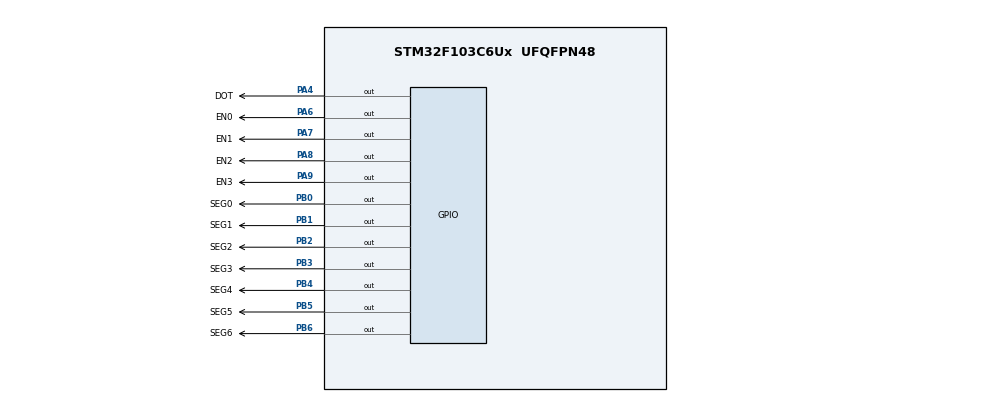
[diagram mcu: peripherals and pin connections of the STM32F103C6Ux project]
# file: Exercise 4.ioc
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Mcu.Family=STM32F1
Mcu.Name=STM32F103C6Ux
Mcu.Package=UFQFPN48
NVIC.PriorityGroup=NVIC_PRIORITYGROUP_4
NVIC.TIM1_BRK_IRQn=true\:0\:0\:false\:false\:true\:true\:true
NVIC.TIM1_CC_IRQn=true\:0\:0\:false\:false\:true\:true\:true
NVIC.TIM1_TRG_COM_IRQn=true\:0\:0\:false\:false\:true\:true\:true
NVIC.TIM1_UP_IRQn=true\:0\:0\:false\:false\:true\:true\:true
NVIC.TIM2_IRQn=true\:0\:0\:false\:false\:true\:true\:true
PA4.GPIO_Label=DOT
PA4.Signal=GPIO_Output
PA6.GPIO_Label=EN0
PA6.Signal=GPIO_Output
PA7.GPIO_Label=EN1
PA7.Signal=GPIO_Output
PA8.GPIO_Label=EN2
PA8.Signal=GPIO_Output
PA9.GPIO_Label=EN3
PA9.Signal=GPIO_Output
PB0.GPIO_Label=SEG0
PB0.Signal=GPIO_Output
PB1.GPIO_Label=SEG1
PB1.Signal=GPIO_Output
PB2.GPIO_Label=SEG2
PB2.Signal=GPIO_Output
PB3.GPIO_Label=SEG3
PB3.Signal=GPIO_Output
PB4.GPIO_Label=SEG4
PB4.Signal=GPIO_Output
PB5.GPIO_Label=SEG5
PB5.Signal=GPIO_Output
PB6.GPIO_Label=SEG6
PB6.Signal=GPIO_Output
ProjectManager.HeapSize=0x200
ProjectManager.StackSize=0x400
ProjectManager.TargetToolchain=STM32CubeIDE
RCC.APB1Freq_Value=8000000
RCC.APB2Freq_Value=8000000
TIM1.Period=9
TIM1.Prescaler=7999
TIM2.Period=9
TIM2.Prescaler=7999
VP_SYS_VS_ND.Mode=No_Debug
VP_TIM1_VS_ClockSourceINT.Mode=Internal
VP_TIM2_VS_ClockSourceINT.Mode=Internal
board=custom

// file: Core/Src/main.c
/* USER CODE BEGIN Header */
/**
  ******************************************************************************
  * @file           : main.c
  * @brief          : Main program body
  ******************************************************************************
  * @attention
  *
  * <h2><center>&copy; Copyright (c) 2023 STMicroelectronics.
  * All rights reserved.</center></h2>
  *
  * This software component is licensed by ST under BSD 3-Clause license,
  * the "License"; You may not use this file except in compliance with the
  * License. You may obtain a copy of the License at:
  *                        opensource.org/licenses/BSD-3-Clause
  *
  ******************************************************************************
  */
/* USER CODE END Header */
#include "main.h"

/* USER CODE BEGIN Includes */
#include "software_timer.h"
/* USER CODE END Includes */

TIM_HandleTypeDef htim1;
TIM_HandleTypeDef htim2;

void SystemClock_Config(void);
static void MX_GPIO_Init(void);
static void MX_TIM1_Init(void);
static void MX_TIM2_Init(void);

int main(void)
{

  /* MCU Configuration--------------------------------------------------------*/

  /* Reset of all peripherals, Initializes the Flash interface and the Systick. */
  HAL_Init();

  /* Configure the system clock */
  SystemClock_Config();

  /* Initialize all configured peripherals */
  MX_GPIO_Init();
  MX_TIM1_Init();
  MX_TIM2_Init();
  /* USER CODE BEGIN 2 */
  HAL_TIM_Base_Start_IT(&htim1);
  HAL_TIM_Base_Start_IT(&htim2);
  /* USER CODE END 2 */

  /* Infinite loop */
  void display7SEG(int num) {
     	  char segNumber[10] = {0xC0, 0xF9, 0xA4, 0xB0, 0x99, 0x92, 0x82, 0xF8, 0x80, 0x90};
         for (int i = 0; i < 7; ++i) {
         	  HAL_GPIO_WritePin(GPIOB, GPIO_PIN_0 << i, (segNumber[num] >> i) & 1);
           }
       }
   int index_led = 0;
   int led_buffer [4] = {1,2,3,0};
   void update7SEG(int index){
 	  switch (index){
 	  	  case 0:
 	  		  display7SEG(led_buffer[0]);
 	  		  HAL_GPIO_WritePin(GPIOA, EN0_Pin, RESET);
 	  		  HAL_GPIO_WritePin(GPIOA, EN1_Pin, SET);
 	  		  HAL_GPIO_WritePin(GPIOA, EN2_Pin, SET);
 	  		  HAL_GPIO_WritePin(GPIOA, EN3_Pin, SET);
 	  		  break;
 	  	  case 1:
 	  		  display7SEG(led_buffer[1]);
 	  		  HAL_GPIO_WritePin(GPIOA, EN0_Pin, SET);
 	  		  HAL_GPIO_WritePin(GPIOA, EN1_Pin, RESET);
 	  		  HAL_GPIO_WritePin(GPIOA, EN2_Pin, SET);
 	  		  HAL_GPIO_WritePin(GPIOA, EN3_Pin, SET);
 	  		  break;
 	  	  case 2:
 	  		  display7SEG(led_buffer[2]);
 	  		  HAL_GPIO_WritePin(GPIOA, EN0_Pin, SET);
 	  		  HAL_GPIO_WritePin(GPIOA, EN1_Pin, SET);
 	  	      HAL_GPIO_WritePin(GPIOA, EN2_Pin, RESET);
 	  		  HAL_GPIO_WritePin(GPIOA, EN3_Pin, SET);
 	  		  break;
 	  	  case 3:
 	  		  display7SEG(led_buffer[3]);
 	  		  HAL_GPIO_WritePin(GPIOA, EN0_Pin, SET);
 	  		  HAL_GPIO_WritePin(GPIOA, EN1_Pin, SET);
 	  		  HAL_GPIO_WritePin(GPIOA, EN2_Pin, SET);
 	  		  HAL_GPIO_WritePin(GPIOA, EN3_Pin, RESET);
 	  		  break;
 	  	  default:
 	  		  break;
 	  }
   }
   setTimer1(01);
   setTimer2(01);
  /* USER CODE BEGIN WHILE */
  while (1)
  {
	  if (timer1_flag == 1){
	  	  setTimer1(100);
	  	  HAL_GPIO_TogglePin(GPIOA, DOT_Pin);
	  }
	  if (timer2_flag == 1){
		  setTimer2(25);
		  update7SEG(index_led++);
		  if(index_led >= 4) index_led = 0;
	  }
    /* USER CODE END WHILE */

  }
}

void SystemClock_Config(void)
{
  RCC_OscInitTypeDef RCC_OscInitStruct = {0};
  RCC_ClkInitTypeDef RCC_ClkInitStruct = {0};

  /** Initializes the RCC Oscillators according to the specified parameters
  * in the RCC_OscInitTypeDef structure.
  */
  RCC_OscInitStruct.OscillatorType = RCC_OSCILLATORTYPE_HSI;
  RCC_OscInitStruct.HSIState = RCC_HSI_ON;
  RCC_OscInitStruct.HSICalibrationValue = RCC_HSICALIBRATION_DEFAULT;
  RCC_OscInitStruct.PLL.PLLState = RCC_PLL_NONE;
  if (HAL_RCC_OscConfig(&RCC_OscInitStruct) != HAL_OK)
  {
    Error_Handler();
  }
  /** Initializes the CPU, AHB and APB buses clocks
  */
  RCC_ClkInitStruct.ClockType = RCC_CLOCKTYPE_HCLK|RCC_CLOCKTYPE_SYSCLK
                              |RCC_CLOCKTYPE_PCLK1|RCC_CLOCKTYPE_PCLK2;
  RCC_ClkInitStruct.SYSCLKSource = RCC_SYSCLKSOURCE_HSI;
  RCC_ClkInitStruct.AHBCLKDivider = RCC_SYSCLK_DIV1;
  RCC_ClkInitStruct.APB1CLKDivider = RCC_HCLK_DIV1;
  RCC_ClkInitStruct.APB2CLKDivider = RCC_HCLK_DIV1;

  if (HAL_RCC_ClockConfig(&RCC_ClkInitStruct, FLASH_LATENCY_0) != HAL_OK)
  {
    Error_Handler();
  }
}

static void MX_TIM1_Init(void)
{

  TIM_ClockConfigTypeDef sClockSourceConfig = {0};
  TIM_MasterConfigTypeDef sMasterConfig = {0};

  htim1.Instance = TIM1;
  htim1.Init.Prescaler = 7999;
  htim1.Init.CounterMode = TIM_COUNTERMODE_UP;
  htim1.Init.Period = 9;
  htim1.Init.ClockDivision = TIM_CLOCKDIVISION_DIV1;
  htim1.Init.RepetitionCounter = 0;
  htim1.Init.AutoReloadPreload = TIM_AUTORELOAD_PRELOAD_DISABLE;
  if (HAL_TIM_Base_Init(&htim1) != HAL_OK)
  {
    Error_Handler();
  }
  sClockSourceConfig.ClockSource = TIM_CLOCKSOURCE_INTERNAL;
  if (HAL_TIM_ConfigClockSource(&htim1, &sClockSourceConfig) != HAL_OK)
  {
    Error_Handler();
  }
  sMasterConfig.MasterOutputTrigger = TIM_TRGO_RESET;
  sMasterConfig.MasterSlaveMode = TIM_MASTERSLAVEMODE_DISABLE;
  if (HAL_TIMEx_MasterConfigSynchronization(&htim1, &sMasterConfig) != HAL_OK)
  {
    Error_Handler();
  }

}

static void MX_TIM2_Init(void)
{

  TIM_ClockConfigTypeDef sClockSourceConfig = {0};
  TIM_MasterConfigTypeDef sMasterConfig = {0};

  htim2.Instance = TIM2;
  htim2.Init.Prescaler = 7999;
  htim2.Init.CounterMode = TIM_COUNTERMODE_UP;
  htim2.Init.Period = 9;
  htim2.Init.ClockDivision = TIM_CLOCKDIVISION_DIV1;
  htim2.Init.AutoReloadPreload = TIM_AUTORELOAD_PRELOAD_DISABLE;
  if (HAL_TIM_Base_Init(&htim2) != HAL_OK)
  {
    Error_Handler();
  }
  sClockSourceConfig.ClockSource = TIM_CLOCKSOURCE_INTERNAL;
  if (HAL_TIM_ConfigClockSource(&htim2, &sClockSourceConfig) != HAL_OK)
  {
    Error_Handler();
  }
  sMasterConfig.MasterOutputTrigger = TIM_TRGO_RESET;
  sMasterConfig.MasterSlaveMode = TIM_MASTERSLAVEMODE_DISABLE;
  if (HAL_TIMEx_MasterConfigSynchronization(&htim2, &sMasterConfig) != HAL_OK)
  {
    Error_Handler();
  }

}

static void MX_GPIO_Init(void)
{
  GPIO_InitTypeDef GPIO_InitStruct = {0};

  /* GPIO Ports Clock Enable */
  __HAL_RCC_GPIOA_CLK_ENABLE();
  __HAL_RCC_GPIOB_CLK_ENABLE();

  /*Configure GPIO pin Output Level */
  HAL_GPIO_WritePin(GPIOA, DOT_Pin|EN0_Pin|EN1_Pin|EN2_Pin
                          |EN3_Pin, GPIO_PIN_RESET);

  /*Configure GPIO pin Output Level */
  HAL_GPIO_WritePin(GPIOB, SEG0_Pin|SEG1_Pin|SEG2_Pin|SEG3_Pin
                          |SEG4_Pin|SEG5_Pin|SEG6_Pin, GPIO_PIN_RESET);

  /*Configure GPIO pins : DOT_Pin EN0_Pin EN1_Pin EN2_Pin
                           EN3_Pin */
  GPIO_InitStruct.Pin = DOT_Pin|EN0_Pin|EN1_Pin|EN2_Pin
                          |EN3_Pin;
  GPIO_InitStruct.Mode = GPIO_MODE_OUTPUT_PP;
  GPIO_InitStruct.Pull = GPIO_NOPULL;
  GPIO_InitStruct.Speed = GPIO_SPEED_FREQ_LOW;
  HAL_GPIO_Init(GPIOA, &GPIO_InitStruct);

  /*Configure GPIO pins : SEG0_Pin SEG1_Pin SEG2_Pin SEG3_Pin
                           SEG4_Pin SEG5_Pin SEG6_Pin */
  GPIO_InitStruct.Pin = SEG0_Pin|SEG1_Pin|SEG2_Pin|SEG3_Pin
                          |SEG4_Pin|SEG5_Pin|SEG6_Pin;
  GPIO_InitStruct.Mode = GPIO_MODE_OUTPUT_PP;
  GPIO_InitStruct.Pull = GPIO_NOPULL;
  GPIO_InitStruct.Speed = GPIO_SPEED_FREQ_LOW;
  HAL_GPIO_Init(GPIOB, &GPIO_InitStruct);

}

/* USER CODE BEGIN 4 */
  void HAL_TIM_PeriodElapsedCallback(TIM_HandleTypeDef *htim){
	  timerRun();
  }
/* USER CODE END 4 */

void Error_Handler(void)
{
  __disable_irq();
  while (1)
  {
  }
}

/************************ (C) COPYRIGHT STMicroelectronics *****END OF FILE****/
